# CY8C3246PVI_147 register map
File version: 0.1
CY8C32
Registers are 8-bit, read-write, no defined reset value unless marked. A register's access mark holds for its fields unless they carry their own. Offsets are from the block's base; lines under a group give offsets from that group; [hi:lo] are bit positions; {n}, {i} and the like mark numbered series; 'fields as' and 'values as' point back to an identical list; <NAME> marks a mode.

## Memory map
0x000043AA ADC size 0x17E0
0x0000642B UART_RS485 size 0x45 — UART
0x0000642D PWM_MOTORS size 0x71
0x00006475 MOTOR_ON_OFF size 0x1
0x00006476 LED_REG size 0x1
0x00006477 FTDI_ENABLE_REG size 0x1
0x0000647C COUNTER_ENC size 0x11C
0x0000647D MOTOR_DIR size 0x1
0x0000657B RS485_CTS size 0x1

## LED_REG
Base 0x00006476
0x00 LED_REG_CONTROL_REG

## FTDI_ENABLE_REG
Base 0x00006477
Registers as LED_REG (with LED_REG read as FTDI_ENABLE_REG).

## MOTOR_ON_OFF
Base 0x00006475
Registers as LED_REG (with LED_REG read as MOTOR_ON_OFF).

## RS485_CTS
Base 0x0000657B
Registers as LED_REG (with LED_REG read as RS485_CTS).

## MOTOR_DIR
Base 0x0000647D
Registers as LED_REG (with LED_REG read as MOTOR_DIR).

## PWM_MOTORS
Base 0x0000642D
0x00 PWM_MOTORS__COMPARE1 — UDB.D0 - Assigned Compare1 Value
0x10 PWM_MOTORS__COMPARE2 — UDB.D1 - Assigned Compare2 Value
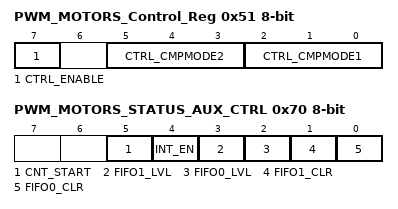
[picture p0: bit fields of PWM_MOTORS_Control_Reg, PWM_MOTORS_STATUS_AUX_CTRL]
0x51 PWM_MOTORS_Control_Reg — UDB Control Register - Assigned Control Register Value
  [7] CTRL_ENABLE — Enable the PWM
  [5:3] CTRL_CMPMODE2 — Compare mode 2
  [2:0] CTRL_CMPMODE1 — Compare mode 1
0x70 PWM_MOTORS_STATUS_AUX_CTRL — UDB Auxilliary Control Register
  [5] CNT_START — FIFO0 clear
    0=E_CNT_START0 (Disable counter); 1=E_CNT_START1 (Enable counter)
  [4] INT_EN
    0=E_INT_EN0 (Interrupt disabled); 1=E_INT_EN1 (Interrupt enabled)
  [3] FIFO1_LVL — FIFO level
    0=E_FIFO_LVL_0 (FIFO LVL: input mode: FIFO not full; output mode: FIFO not empty); 1=E_FIFO_LVL_1 (FIFO LVL: input mode: FIFO at least 1/2 empty; output mode: FIFO at least 1/2 full)
  [2] FIFO0_LVL — FIFO level
    values as FIFO1_LVL
  [1] FIFO1_CLR — FIFO1 clear
    0=E_FIFO_CLR_0 (Normal FIFO operation); 1=E_FIFO_CLR_1 (Clear FIFO state)
  [0] FIFO0_CLR — FIFO0 clear
    values as FIFO1_CLR

## UART_RS485 — UART
Base 0x0000642B
0x00 RX_UART_RS485_RX_ADDRESS1 — RX Address1 Register
0x10 RX_UART_RS485_RX_ADDRESS2 — RX Address2 Register
0x20 RX_UART_RS485_RX_DATA — RX Data Register
0x24 TX_UART_RS485_TX_DATA — TX Data Register
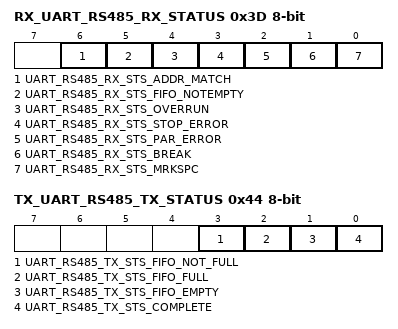
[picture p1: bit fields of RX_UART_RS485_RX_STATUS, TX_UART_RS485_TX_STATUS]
0x3D RX_UART_RS485_RX_STATUS — RX status register
  [6] UART_RS485_RX_STS_ADDR_MATCH ro, [5] UART_RS485_RX_STS_FIFO_NOTEMPTY ro, [4] UART_RS485_RX_STS_OVERRUN ro, [3] UART_RS485_RX_STS_STOP_ERROR ro, [2] UART_RS485_RX_STS_PAR_ERROR ro, [1] UART_RS485_RX_STS_BREAK ro, [0] UART_RS485_RX_STS_MRKSPC ro
0x44 TX_UART_RS485_TX_STATUS — TX status register
  [3] UART_RS485_TX_STS_FIFO_NOT_FULL ro, [2] UART_RS485_TX_STS_FIFO_FULL ro, [1] UART_RS485_TX_STS_FIFO_EMPTY ro, [0] UART_RS485_TX_STS_COMPLETE ro

## COUNTER_ENC
Base 0x0000647C
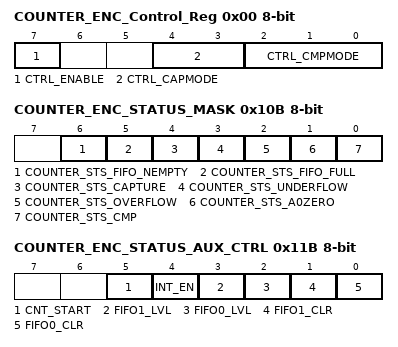
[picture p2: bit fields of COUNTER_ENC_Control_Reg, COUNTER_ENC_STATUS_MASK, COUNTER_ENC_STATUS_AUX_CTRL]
0x00 COUNTER_ENC_Control_Reg — UDB Control Register - Assigned Control Register Value
  [7] CTRL_ENABLE — Enable Counter
  [4:3] CTRL_CAPMODE — Capture mode
  [2:0] CTRL_CMPMODE — Compare mode
0x8B COUNTER_ENC_COUNTER — UDB.A0 - Current Counter Value
0xAB COUNTER_ENC_PERIOD — UDB.D0 - Assigned Period
0xBB COUNTER_ENC_COMPARE — UDB.D1 - Assigned Compare Value
0x10B COUNTER_ENC_STATUS_MASK — UDB Status bits Interrupt Mask Enable Register
  [6] COUNTER_STS_FIFO_NEMPTY — FIFO Not Empty Status
  [5] COUNTER_STS_FIFO_FULL — FIFO Full Status
  [4] COUNTER_STS_CAPTURE — Capture Status
  [3] COUNTER_STS_UNDERFLOW — Underflow status
  [2] COUNTER_STS_OVERFLOW — Overflow status
  [1] COUNTER_STS_A0ZERO — A0 Zero ouput status
  [0] COUNTER_STS_CMP — Compare output status
0x11B COUNTER_ENC_STATUS_AUX_CTRL — UDB Auxilliary Control Register
  [5] CNT_START — FIFO0 clear
    0=E_CNT_START0 (Disable counter); 1=E_CNT_START1 (Enable counter)
  [4] INT_EN
    0=E_INT_EN0 (Interrupt disabled); 1=E_INT_EN1 (Interrupt enabled)
  [3] FIFO1_LVL — FIFO level
    0=E_FIFO_LVL_0 (FIFO LVL: input mode: FIFO not full; output mode: FIFO not empty); 1=E_FIFO_LVL_1 (FIFO LVL: input mode: FIFO at least 1/2 empty; output mode: FIFO at least 1/2 full)
  [2] FIFO0_LVL — FIFO level
    values as FIFO1_LVL
  [1] FIFO1_CLR — FIFO1 clear
    0=E_FIFO_CLR_0 (Normal FIFO operation); 1=E_FIFO_CLR_1 (Clear FIFO state)
  [0] FIFO0_CLR — FIFO0 clear
    values as FIFO1_CLR
